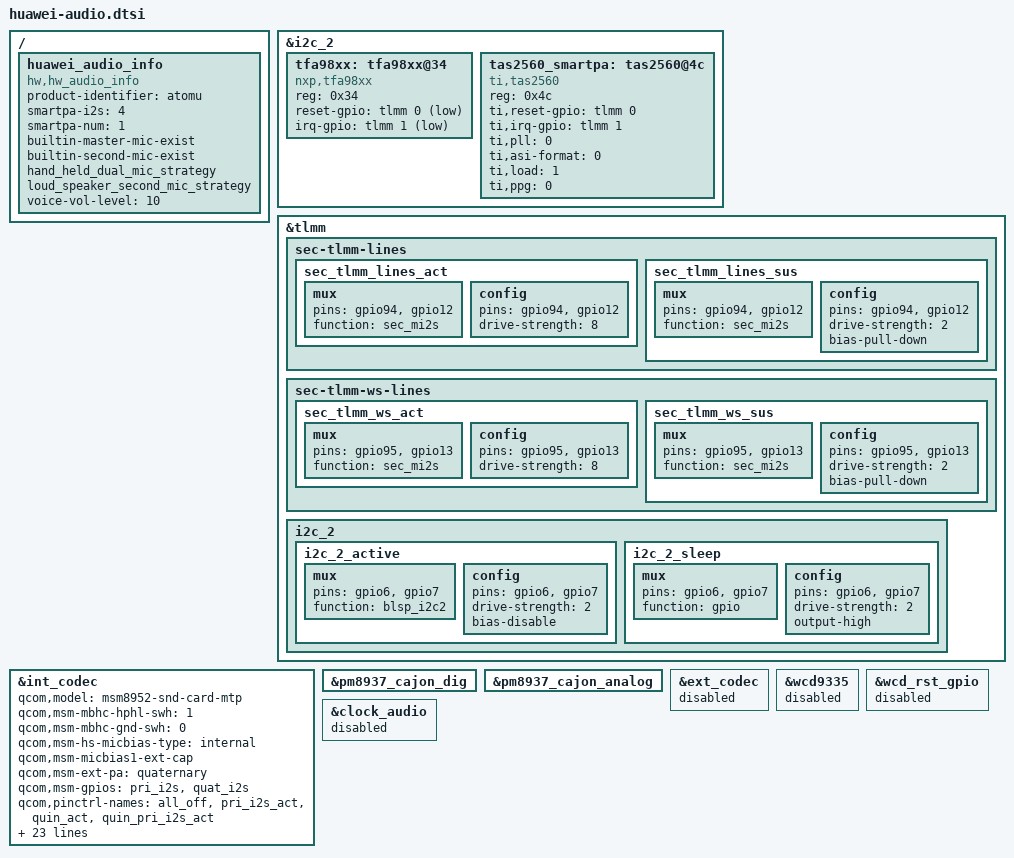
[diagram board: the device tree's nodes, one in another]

/ {
    huawei_audio_info {
        compatible = "hw,hw_audio_info";
        product-identifier = "atomu";
        smartpa-i2s = <4>;
        smartpa-num = <1>;
        builtin-master-mic-exist;
        builtin-second-mic-exist;
        hand_held_dual_mic_strategy;
        loud_speaker_second_mic_strategy;
        voice-vol-level = <10>;
        status = "ok";
    };
};

/* delete node for wsa spk config of qcom */
&i2c_2 {
    /delete-node/ wsa881x-i2c-codec@e;
    /delete-node/ wsa881x-i2c-codec@44;
    /delete-node/ wsa881x-i2c-codec@f;
    /delete-node/ wsa881x-i2c-codec@45;
};

&tlmm {
    sec-tlmm-lines {
        sec_tlmm_lines_act: sec_tlmm_lines_act {
            mux {
                pins = "gpio94", "gpio12";
                function = "sec_mi2s";
            };

            config {
                pins = "gpio94", "gpio12";
                drive-strength = <8>;
            };
        };

        sec_tlmm_lines_sus: sec_tlmm_lines_sus {
            mux {
                pins = "gpio94", "gpio12";
                function = "sec_mi2s";
            };

            config {
                pins = "gpio94", "gpio12";
                drive-strength = <2>;
                bias-pull-down;
            };
        };
    };

    sec-tlmm-ws-lines {
        sec_tlmm_ws_act: sec_tlmm_ws_act {
            mux {
                pins = "gpio95" , "gpio13";
                function = "sec_mi2s";
            };

            config {
                pins = "gpio95" , "gpio13";
                drive-strength = <8>;
            };
        };

        sec_tlmm_ws_sus: sec_tlmm_ws_sus {
            mux {
                pins = "gpio95" , "gpio13";
                function = "sec_mi2s";
            };

            config {
                pins = "gpio95" , "gpio13";
                drive-strength = <2>;
                bias-pull-down;
            };
        };
    };

    i2c_2 {
        i2c_2_active: i2c_2_active {
            /* active state */
            mux {
                pins = "gpio6", "gpio7";
                function = "blsp_i2c2";
            };

            config {
                pins = "gpio6", "gpio7";
                drive-strength = <2>;
                bias-disable;
            };
        };

        i2c_2_sleep: i2c_2_sleep {
            /* suspended state */
            mux {
                pins = "gpio6", "gpio7";
                function = "gpio";
            };

            config {
                pins = "gpio6", "gpio7";
                drive-strength = <2>;
                output-high;
            };
        };
    };
};

&i2c_2 {
    status = "okay";
    tfa98xx: tfa98xx@34 {
        compatible = "nxp,tfa98xx";
        reg = <0x34>;
        reset-gpio = <&tlmm 0 0x01>;
        irq-gpio = <&tlmm 1 0x01>;
        status = "okay";
    };

    tas2560_smartpa:tas2560@4c {
        compatible = "ti,tas2560";
        reg = <0x4c>;
        ti,reset-gpio = <&tlmm 0 0>;
        ti,irq-gpio = <&tlmm 1 0>;
        ti,pll = <0>; /* refer to tas2560.h for more details */
        ti,asi-format = <0>; /* 0, i2S; 1, DSP; */
        ti,load = <1>; /* 0,8Ohm; 1, 6Ohm; 2, 4Ohm */
        ti,ppg = <0>; /* 0,0dB default; 1,enable -2dB */
        status = "ok";
    };
};

&int_codec {
    status = "okay";
    /delete-property/ qcom,cdc-us-euro-gpios; /* There is no switch for US-EURO headsets */
    /delete-property/ qcom,hdmi-dba-codec-rx; /* not support hdmi feature */
    /delete-property/ asoc-wsa-codec-names;
    /delete-property/ asoc-wsa-codec-prefixes;
    /delete-property/ msm-vdd-wsa-switch-supply;
    /delete-property/ qcom,msm-vdd-wsa-switch-voltage;
    /delete-property/ qcom,msm-vdd-wsa-switch-current;

    qcom,model = "msm8952-snd-card-mtp";
    qcom,msm-mbhc-hphl-swh = <1>;
    qcom,msm-mbhc-gnd-swh = <0>;
    qcom,msm-hs-micbias-type = "internal";
    qcom,msm-micbias1-ext-cap;
    qcom,msm-ext-pa = "quaternary";

    qcom,msm-gpios =
            "pri_i2s",
            "quat_i2s";
    qcom,pinctrl-names =
            "all_off",
            "pri_i2s_act",
            "quin_act",
            "quin_pri_i2s_act";
    pinctrl-names =
            "all_off",
            "pri_i2s_act",
            "quin_act",
            "quin_pri_i2s_act";
    pinctrl-0 = <&cdc_pdm_lines_sus
            &cdc_pdm_lines_2_sus
            &sec_tlmm_lines_sus &sec_tlmm_ws_sus>;
    pinctrl-1 = <&cdc_pdm_lines_act
            &cdc_pdm_lines_2_act
            &sec_tlmm_lines_sus &sec_tlmm_ws_sus>;
    pinctrl-2 = <&cdc_pdm_lines_sus
            &cdc_pdm_lines_2_sus
            &sec_tlmm_lines_act &sec_tlmm_ws_act>;
    pinctrl-3 = <&cdc_pdm_lines_act
            &cdc_pdm_lines_2_act
            &sec_tlmm_lines_act &sec_tlmm_ws_act>;

    qcom,audio-routing =
        "RX_BIAS", "MCLK",
        "SPK_RX_BIAS", "MCLK",
        "INT_LDO_H", "MCLK",
        "MIC BIAS External", "Handset Mic",
        "MIC BIAS Internal2", "Headset Mic",
        "MIC BIAS External", "Secondary Mic",
        "AMIC1", "MIC BIAS External",
        "AMIC2", "MIC BIAS Internal2",
        "AMIC3", "MIC BIAS External";

    asoc-codec = <&stub_codec>, <&pm8937_cajon_dig>, <&hdmi_dba>;
    asoc-codec-names = "msm-stub-codec.1", "cajon_codec",
                        "msm-hdmi-dba-codec-rx";
};

&pm8937_cajon_dig {
    status = "okay";
};

&pm8937_cajon_analog {
    status = "okay";
};

&ext_codec {
    status = "disabled";
};

&wcd9335 {
    status = "disabled";
};

&wcd_rst_gpio {
    status = "disabled";
};

&clock_audio {
    status = "disabled";
};
